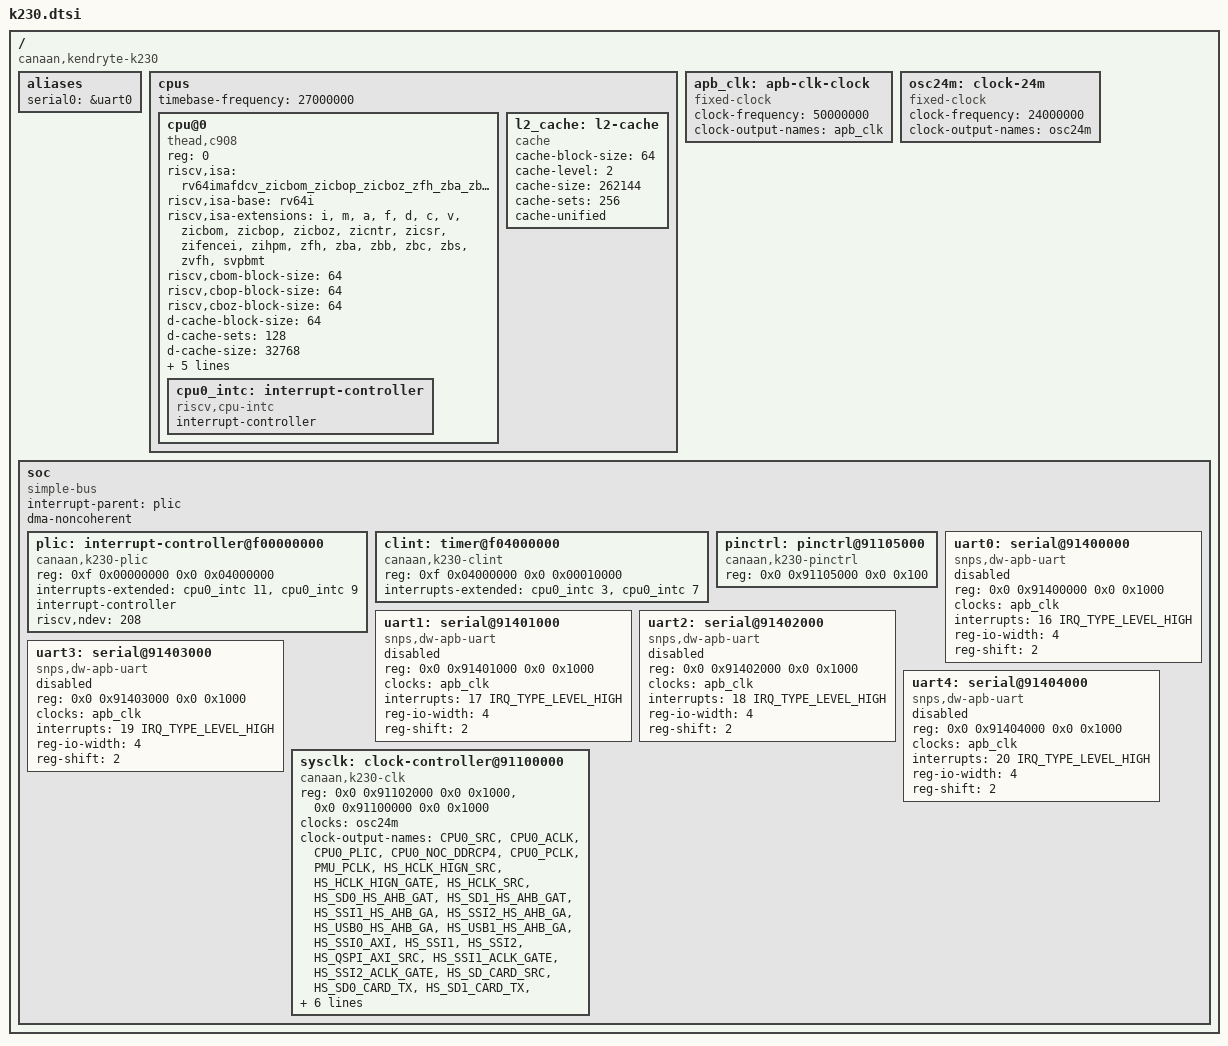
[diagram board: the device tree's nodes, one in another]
// SPDX-License-Identifier: GPL-2.0 OR MIT
/*
 * Copyright (C) 2024 Yangyu Chen <cyy@cyyself.name>
 */

#include <dt-bindings/interrupt-controller/irq.h>
#include <dt-bindings/clock/k230-clk.h>
#include "k230-pinctrl.h"

/dts-v1/;
/ {
	#address-cells = <2>;
	#size-cells = <2>;
	compatible = "canaan,kendryte-k230";

	aliases {
		serial0 = &uart0;
	};

	cpus {
		#address-cells = <1>;
		#size-cells = <0>;
		timebase-frequency = <27000000>;

		cpu@0 {
			compatible = "thead,c908", "riscv";
			device_type = "cpu";
			reg = <0>;
			riscv,isa = "rv64imafdcv_zicbom_zicbop_zicboz_zfh_zba_zbb_zbc_zbs_zvfh_svpbmt";
			riscv,isa-base = "rv64i";
			riscv,isa-extensions = "i", "m", "a", "f", "d", "c", "v", "zicbom",
					       "zicbop", "zicboz", "zicntr", "zicsr", "zifencei",
					       "zihpm", "zfh", "zba", "zbb", "zbc", "zbs", "zvfh",
					       "svpbmt";
			riscv,cbom-block-size = <64>;
			riscv,cbop-block-size = <64>;
			riscv,cboz-block-size = <64>;
			d-cache-block-size = <64>;
			d-cache-sets = <128>;
			d-cache-size = <32768>;
			i-cache-block-size = <64>;
			i-cache-sets = <128>;
			i-cache-size = <32768>;
			next-level-cache = <&l2_cache>;
			mmu-type = "riscv,sv39";

			cpu0_intc: interrupt-controller {
				compatible = "riscv,cpu-intc";
				interrupt-controller;
				#interrupt-cells = <1>;
			};
		};

		l2_cache: l2-cache {
			compatible = "cache";
			cache-block-size = <64>;
			cache-level = <2>;
			cache-size = <262144>;
			cache-sets = <256>;
			cache-unified;
		};
	};

	apb_clk: apb-clk-clock {
		compatible = "fixed-clock";
		clock-frequency = <50000000>;
		clock-output-names = "apb_clk";
		#clock-cells = <0>;
	};

	osc24m: clock-24m{
		compatible = "fixed-clock";
		#clock-cells = <0>;
		clock-frequency = <24000000>;
		clock-output-names = "osc24m";
		status = "okay";
	};

	soc {
		compatible = "simple-bus";
		interrupt-parent = <&plic>;
		#address-cells = <2>;
		#size-cells = <2>;
		dma-noncoherent;
		ranges;

		plic: interrupt-controller@f00000000 {
			compatible = "canaan,k230-plic" ,"thead,c900-plic";
			reg = <0xf 0x00000000 0x0 0x04000000>;
			interrupts-extended = <&cpu0_intc 11>, <&cpu0_intc 9>;
			interrupt-controller;
			#address-cells = <0>;
			#interrupt-cells = <2>;
			riscv,ndev = <208>;
		};

		clint: timer@f04000000 {
			compatible = "canaan,k230-clint", "thead,c900-clint";
			reg = <0xf 0x04000000 0x0 0x00010000>;
			interrupts-extended = <&cpu0_intc 3>, <&cpu0_intc 7>;
		};

		pinctrl: pinctrl@91105000 {
			compatible = "canaan,k230-pinctrl";
			reg = <0x0 0x91105000 0x0 0x100>;
		};

		uart0: serial@91400000 {
			compatible = "snps,dw-apb-uart";
			reg = <0x0 0x91400000 0x0 0x1000>;
			clocks = <&apb_clk>;
			interrupts = <16 IRQ_TYPE_LEVEL_HIGH>;
			reg-io-width = <4>;
			reg-shift = <2>;
			status = "disabled";
		};

		uart1: serial@91401000 {
			compatible = "snps,dw-apb-uart";
			reg = <0x0 0x91401000 0x0 0x1000>;
			clocks = <&apb_clk>;
			interrupts = <17 IRQ_TYPE_LEVEL_HIGH>;
			reg-io-width = <4>;
			reg-shift = <2>;
			status = "disabled";
		};

		uart2: serial@91402000 {
			compatible = "snps,dw-apb-uart";
			reg = <0x0 0x91402000 0x0 0x1000>;
			clocks = <&apb_clk>;
			interrupts = <18 IRQ_TYPE_LEVEL_HIGH>;
			reg-io-width = <4>;
			reg-shift = <2>;
			status = "disabled";
		};

		uart3: serial@91403000 {
			compatible = "snps,dw-apb-uart";
			reg = <0x0 0x91403000 0x0 0x1000>;
			clocks = <&apb_clk>;
			interrupts = <19 IRQ_TYPE_LEVEL_HIGH>;
			reg-io-width = <4>;
			reg-shift = <2>;
			status = "disabled";
		};

		uart4: serial@91404000 {
			compatible = "snps,dw-apb-uart";
			reg = <0x0 0x91404000 0x0 0x1000>;
			clocks = <&apb_clk>;
			interrupts = <20 IRQ_TYPE_LEVEL_HIGH>;
			reg-io-width = <4>;
			reg-shift = <2>;
			status = "disabled";
		};

		sysclk: clock-controller@91100000 {
			compatible = "canaan,k230-clk";
			reg = <0x0 0x91102000 0x0 0x1000>, <0x0 0x91100000 0x0 0x1000>;
			clocks = <&osc24m>;
			#clock-cells = <1>;
			clock-output-names = "CPU0_SRC",
			"CPU0_ACLK", "CPU0_PLIC", "CPU0_NOC_DDRCP4", "CPU0_PCLK",
			"PMU_PCLK", "HS_HCLK_HIGN_SRC", "HS_HCLK_HIGN_GATE",
			"HS_HCLK_SRC", "HS_SD0_HS_AHB_GAT", "HS_SD1_HS_AHB_GAT",
			"HS_SSI1_HS_AHB_GA", "HS_SSI2_HS_AHB_GA", "HS_USB0_HS_AHB_GA",
			"HS_USB1_HS_AHB_GA", "HS_SSI0_AXI", "HS_SSI1", "HS_SSI2",
			"HS_QSPI_AXI_SRC", "HS_SSI1_ACLK_GATE", "HS_SSI2_ACLK_GATE",
			"HS_SD_CARD_SRC", "HS_SD0_CARD_TX", "HS_SD1_CARD_TX",
			"HS_SD_AXI_SRC", "HS_SD0_AXI_GATE", "HS_SD1_AXI_GATE",
			"HS_SD0_BASE_GATE", "HS_SD1_BASE_GATE", "HS_OSPI_SRC",
			"HS_USB_REF_51M", "HS_SD_TIMER_SRC", "HS_SD0_TIMER_GATE",
			"HS_SD1_TIMER_GATE", "HS_USB0_REFERENCE", "HS_USB1_REFERENCE";
			status = "okay";
		};
	};
};
